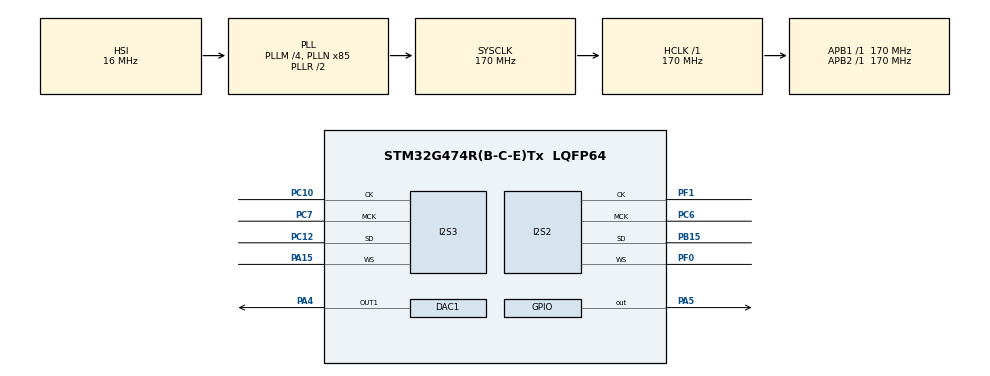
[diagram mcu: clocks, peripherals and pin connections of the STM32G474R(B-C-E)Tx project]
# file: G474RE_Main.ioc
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DAC1.DAC_HighFrequency_OUT1-DAC_OUT1=DAC_HIGH_FREQUENCY_INTERFACE_MODE_AUTOMATIC
DAC1.DAC_OutputBuffer-DAC_OUT1=DAC_OUTPUTBUFFER_DISABLE
DAC1.DAC_SignedFormat-DAC_OUT1=DISABLE
DAC1.DAC_Trigger_OUT1-DAC_OUT1=DAC_TRIGGER_T6_TRGO
Dma.DAC1_CH1.0.Direction=DMA_MEMORY_TO_PERIPH
Dma.DAC1_CH1.0.EventEnable=DISABLE
Dma.DAC1_CH1.0.Instance=DMA1_Channel1
Dma.DAC1_CH1.0.MemDataAlignment=DMA_MDATAALIGN_WORD
Dma.DAC1_CH1.0.MemInc=DMA_MINC_ENABLE
Dma.DAC1_CH1.0.Mode=DMA_CIRCULAR
Dma.DAC1_CH1.0.PeriphDataAlignment=DMA_PDATAALIGN_WORD
Dma.DAC1_CH1.0.PeriphInc=DMA_PINC_DISABLE
Dma.DAC1_CH1.0.Polarity=HAL_DMAMUX_REQ_GEN_RISING
Dma.DAC1_CH1.0.Priority=DMA_PRIORITY_LOW
Dma.DAC1_CH1.0.RequestNumber=1
Dma.DAC1_CH1.0.SignalID=NONE
Dma.DAC1_CH1.0.SyncEnable=DISABLE
Dma.DAC1_CH1.0.SyncPolarity=HAL_DMAMUX_SYNC_NO_EVENT
Dma.DAC1_CH1.0.SyncRequestNumber=1
Dma.DAC1_CH1.0.SyncSignalID=NONE
Dma.Request0=DAC1_CH1
Dma.Request1=SPI2_RX
Dma.Request2=SPI3_TX
Dma.SPI2_RX.1.Direction=DMA_PERIPH_TO_MEMORY
Dma.SPI2_RX.1.EventEnable=DISABLE
Dma.SPI2_RX.1.Instance=DMA1_Channel2
Dma.SPI2_RX.1.MemDataAlignment=DMA_MDATAALIGN_WORD
Dma.SPI2_RX.1.MemInc=DMA_MINC_ENABLE
Dma.SPI2_RX.1.Mode=DMA_CIRCULAR
Dma.SPI2_RX.1.PeriphDataAlignment=DMA_PDATAALIGN_WORD
Dma.SPI2_RX.1.PeriphInc=DMA_PINC_DISABLE
Dma.SPI2_RX.1.Polarity=HAL_DMAMUX_REQ_GEN_RISING
Dma.SPI2_RX.1.Priority=DMA_PRIORITY_LOW
Dma.SPI2_RX.1.RequestNumber=1
Dma.SPI2_RX.1.SignalID=NONE
Dma.SPI2_RX.1.SyncEnable=DISABLE
Dma.SPI2_RX.1.SyncPolarity=HAL_DMAMUX_SYNC_NO_EVENT
Dma.SPI2_RX.1.SyncRequestNumber=1
Dma.SPI2_RX.1.SyncSignalID=NONE
Dma.SPI3_TX.2.Direction=DMA_MEMORY_TO_PERIPH
Dma.SPI3_TX.2.EventEnable=DISABLE
Dma.SPI3_TX.2.Instance=DMA1_Channel3
Dma.SPI3_TX.2.MemDataAlignment=DMA_MDATAALIGN_WORD
Dma.SPI3_TX.2.MemInc=DMA_MINC_ENABLE
Dma.SPI3_TX.2.Mode=DMA_CIRCULAR
Dma.SPI3_TX.2.PeriphDataAlignment=DMA_PDATAALIGN_WORD
Dma.SPI3_TX.2.PeriphInc=DMA_PINC_DISABLE
Dma.SPI3_TX.2.Polarity=HAL_DMAMUX_REQ_GEN_RISING
Dma.SPI3_TX.2.Priority=DMA_PRIORITY_LOW
Dma.SPI3_TX.2.RequestNumber=1
Dma.SPI3_TX.2.SignalID=NONE
Dma.SPI3_TX.2.SyncEnable=DISABLE
Dma.SPI3_TX.2.SyncPolarity=HAL_DMAMUX_SYNC_NO_EVENT
Dma.SPI3_TX.2.SyncRequestNumber=1
Dma.SPI3_TX.2.SyncSignalID=NONE
I2S2.AudioFreq=I2S_AUDIOFREQ_44K
I2S2.DataFormat=I2S_DATAFORMAT_24B
I2S2.ErrorAudioFreq=0.61 %
I2S2.FullDuplexMode=I2S_FULLDUPLEXMODE_DISABLE
I2S2.Instance=SPI$Index
I2S2.Mode=I2S_MODE_MASTER_RX
I2S2.RealAudioFreq=44.27 KHz
I2S2.VirtualMode=I2S_MODE_MASTER
I2S3.AudioFreq=I2S_AUDIOFREQ_44K
I2S3.DataFormat=I2S_DATAFORMAT_24B
I2S3.ErrorAudioFreq=0.61 %
I2S3.FullDuplexMode=I2S_FULLDUPLEXMODE_DISABLE
I2S3.Instance=SPI$Index
I2S3.RealAudioFreq=44.27 KHz
I2S3.VirtualMode=I2S_MODE_MASTER
Mcu.Family=STM32G4
Mcu.Name=STM32G474R(B-C-E)Tx
Mcu.Package=LQFP64
NVIC.DMA1_Channel1_IRQn=true\:0\:0\:false\:false\:true\:false\:true
NVIC.DMA1_Channel2_IRQn=true\:0\:0\:false\:false\:true\:false\:true
NVIC.DMA1_Channel3_IRQn=true\:0\:0\:false\:false\:true\:false\:true
NVIC.PriorityGroup=NVIC_PRIORITYGROUP_4
NVIC.SPI2_IRQn=true\:0\:0\:false\:false\:true\:true\:true
NVIC.SPI3_IRQn=true\:0\:0\:false\:false\:true\:true\:true
NVIC.TIM6_DAC_IRQn=true\:1\:0\:true\:false\:true\:true\:true
NVIC.TIM7_DAC_IRQn=true\:0\:0\:false\:false\:true\:true\:true
PA13.Mode=Trace_Asynchronous_SW
PA13.Signal=SYS_JTMS-SWDIO
PA14.Mode=Trace_Asynchronous_SW
PA14.Signal=SYS_JTCK-SWCLK
PA15.Mode=Half_Duplex_Master
PA15.Signal=I2S3_WS
PA4.Signal=COMP_DAC11_group
PA5.Signal=GPIO_Output
PB15.Mode=Half_Duplex_Master
PB15.Signal=I2S2_SD
PB3.Mode=Trace_Asynchronous_SW
PB3.Signal=SYS_JTDO-SWO
PC10.Mode=Half_Duplex_Master
PC10.Signal=I2S3_CK
PC12.Mode=Half_Duplex_Master
PC12.Signal=I2S3_SD
PC6.Mode=Master_Clock_Activated
PC6.Signal=I2S2_MCK
PC7.Mode=Master_Clock_Activated
PC7.Signal=I2S3_MCK
PF0-OSC_IN.Mode=Half_Duplex_Master
PF0-OSC_IN.Signal=I2S2_WS
PF1-OSC_OUT.Mode=Half_Duplex_Master
PF1-OSC_OUT.Signal=I2S2_CK
ProjectManager.HeapSize=0x200
ProjectManager.StackSize=0x400
ProjectManager.TargetToolchain=STM32CubeIDE
RCC.ADC12Freq_Value=170000000
RCC.ADC345Freq_Value=170000000
RCC.AHBFreq_Value=170000000
RCC.APB1Freq_Value=170000000
RCC.APB1TimFreq_Value=170000000
RCC.APB2Freq_Value=170000000
RCC.APB2TimFreq_Value=170000000
RCC.CortexFreq_Value=170000000
RCC.EXTERNAL_CLOCK_VALUE=12288000
RCC.HCLKFreq_Value=170000000
RCC.HSE_VALUE=8000000
RCC.HSI48_VALUE=48000000
RCC.HSI_VALUE=16000000
RCC.LSE_VALUE=32768
RCC.PLLM=RCC_PLLM_DIV4
RCC.PLLN=85
RCC.SYSCLKFreq_VALUE=170000000
RCC.SYSCLKSource=RCC_SYSCLKSOURCE_PLLCLK
RCC.USBFreq_Value=170000000
RCC.VCOOutputFreq_Value=340000000
SH.COMP_DAC11_group.0=DAC1_OUT1,DAC_OUT1
TIM6.AutoReloadPreload=TIM_AUTORELOAD_PRELOAD_ENABLE
TIM6.PeriodNoDither=1024
TIM6.Prescaler=0
TIM6.TIM_MasterOutputTrigger=TIM_TRGO_UPDATE
TIM7.AutoReloadPreload=TIM_AUTORELOAD_PRELOAD_ENABLE
TIM7.PeriodNoDither=1024
VP_SYS_VS_DBSignals.Mode=DisableDeadBatterySignals
VP_TIM6_VS_ClockSourceINT.Mode=Enable_Timer
VP_TIM7_VS_ClockSourceINT.Mode=Enable_Timer
board=custom

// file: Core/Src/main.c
/* USER CODE BEGIN Header */
/**
  ******************************************************************************
  * @file           : main.c
  * @brief          : Main program body
  ******************************************************************************
  * @attention
  *
  * <h2><center>&copy; Copyright (c) 2021 STMicroelectronics.
  * All rights reserved.</center></h2>
  *
  * This software component is licensed by ST under BSD 3-Clause license,
  * the "License"; You may not use this file except in compliance with the
  * License. You may obtain a copy of the License at:
  *                        opensource.org/licenses/BSD-3-Clause
  *
  ******************************************************************************
  */
/* USER CODE END Header */
#include "main.h"
#include "dac.h"
#include "dma.h"
#include "i2s.h"
#include "tim.h"
#include "gpio.h"

/* USER CODE BEGIN Includes */

#include "appmain.hpp"
#include "test_i2s.hpp"
/* USER CODE END Includes */

/* USER CODE BEGIN PV */
// https://www.daycounter.com/Calculators/Sine-Generator-Calculator.phtml
// NumPoints=64, MaxAmpl=4095, NumPerRow=8, Dec

/* USER CODE END PV */

void SystemClock_Config(void);

int main(void)
{

  /* MCU Configuration--------------------------------------------------------*/

  /* Reset of all peripherals, Initializes the Flash interface and the Systick. */
  HAL_Init();

  /* Configure the system clock */
  SystemClock_Config();

  /* Initialize all configured peripherals */
  MX_GPIO_Init();
  MX_DMA_Init();
  MX_TIM6_Init();
  MX_DAC1_Init();
  MX_TIM7_Init();
  MX_I2S2_Init();
  MX_I2S3_Init();
  /* USER CODE BEGIN 2 */
  test_i2s();
  //appmain();

  // system base test
  /* USER CODE END 2 */

  /* Infinite loop */
  while (1)
  {

  }
}

void SystemClock_Config(void)
{
  RCC_OscInitTypeDef RCC_OscInitStruct = {0};
  RCC_ClkInitTypeDef RCC_ClkInitStruct = {0};
  RCC_PeriphCLKInitTypeDef PeriphClkInit = {0};

  /** Configure the main internal regulator output voltage
  */
  HAL_PWREx_ControlVoltageScaling(PWR_REGULATOR_VOLTAGE_SCALE1_BOOST);
  /** Initializes the RCC Oscillators according to the specified parameters
  * in the RCC_OscInitTypeDef structure.
  */
  RCC_OscInitStruct.OscillatorType = RCC_OSCILLATORTYPE_HSI;
  RCC_OscInitStruct.HSIState = RCC_HSI_ON;
  RCC_OscInitStruct.HSICalibrationValue = RCC_HSICALIBRATION_DEFAULT;
  RCC_OscInitStruct.PLL.PLLState = RCC_PLL_ON;
  RCC_OscInitStruct.PLL.PLLSource = RCC_PLLSOURCE_HSI;
  RCC_OscInitStruct.PLL.PLLM = RCC_PLLM_DIV4;
  RCC_OscInitStruct.PLL.PLLN = 85;
  RCC_OscInitStruct.PLL.PLLP = RCC_PLLP_DIV2;
  RCC_OscInitStruct.PLL.PLLQ = RCC_PLLQ_DIV2;
  RCC_OscInitStruct.PLL.PLLR = RCC_PLLR_DIV2;
  if (HAL_RCC_OscConfig(&RCC_OscInitStruct) != HAL_OK)
  {
    Error_Handler();
  }
  /** Initializes the CPU, AHB and APB buses clocks
  */
  RCC_ClkInitStruct.ClockType = RCC_CLOCKTYPE_HCLK|RCC_CLOCKTYPE_SYSCLK
                              |RCC_CLOCKTYPE_PCLK1|RCC_CLOCKTYPE_PCLK2;
  RCC_ClkInitStruct.SYSCLKSource = RCC_SYSCLKSOURCE_PLLCLK;
  RCC_ClkInitStruct.AHBCLKDivider = RCC_SYSCLK_DIV1;
  RCC_ClkInitStruct.APB1CLKDivider = RCC_HCLK_DIV1;
  RCC_ClkInitStruct.APB2CLKDivider = RCC_HCLK_DIV1;

  if (HAL_RCC_ClockConfig(&RCC_ClkInitStruct, FLASH_LATENCY_4) != HAL_OK)
  {
    Error_Handler();
  }
  /** Initializes the peripherals clocks
  */
  PeriphClkInit.PeriphClockSelection = RCC_PERIPHCLK_I2S;
  PeriphClkInit.I2sClockSelection = RCC_I2SCLKSOURCE_SYSCLK;
  if (HAL_RCCEx_PeriphCLKConfig(&PeriphClkInit) != HAL_OK)
  {
    Error_Handler();
  }
}

void Error_Handler(void)
{
  __disable_irq();
  while (1)
  {
  }
}

/************************ (C) COPYRIGHT STMicroelectronics *****END OF FILE****/
